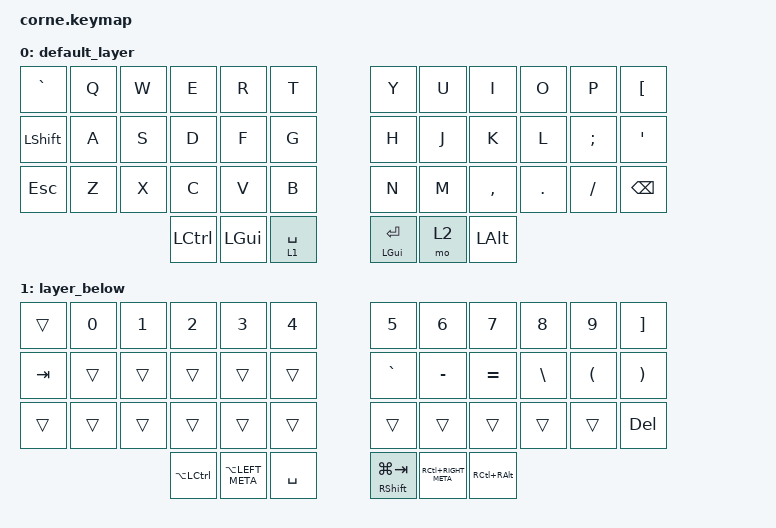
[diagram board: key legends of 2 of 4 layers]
/*
 * Copyright (c) 2020 The ZMK Contributors
 *
 * SPDX-License-Identifier: MIT
 */

#include <dt-bindings/zmk/mouse.h>
#include <behaviors.dtsi>
#include <dt-bindings/zmk/keys.h>
#include <dt-bindings/zmk/outputs.h>
#include <dt-bindings/zmk/pointing.h>

/ {
    behaviors {
        tp: tap_preferred {
            compatible = "zmk,behavior-hold-tap";
            label = "TAP_PREFERRED";
            #binding-cells = <2>;
            tapping-term-ms = <150>;
            quick-tap-ms = <0>;
            flavor = "tap-preferred";
            bindings = <&kp>, <&kp>;
        };
    };

    keymap {
        compatible = "zmk,keymap";

        default_layer {
            // -----------------------------------------------------------------------------------------
            // | TAB  |  Q  |  W  |  E  |  R  |    T    |   |  Y  |  U   |  I  |  O  |  P  |  [   |
            // | CTRL |  A  |  S  |  D  |  F  |    G    |   |  H  |  J   |  K  |  L  |  ;  |  '   |
            // | SHFT |  Z  |  X  |  C  |  V  |    B    |   |  N  |  M   |  ,  |  .  |  /  | BSPC |
            //                    | GUI | LWR | ALT/ENT |   | HYPER/SPC | BKSP  | RSE |

            bindings = <
&kp GRAVE       &kp Q  &kp W  &kp E      &kp R     &kp T          &kp Y           &kp U  &kp I      &kp O    &kp P     &kp LBKT
&kp LEFT_SHIFT  &kp A  &kp S  &kp D      &kp F     &kp G          &kp H           &kp J  &kp K      &kp L    &kp SEMI  &kp APOSTROPHE
&kp ESC         &kp Z  &kp X  &kp C      &kp V     &kp B          &kp N           &kp M  &kp COMMA  &kp DOT  &kp FSLH  &kp BSPC
                              &kp LCTRL  &kp LGUI  &lt 1 SPACE    &tp LGUI ENTER  &mo 2  &kp LALT
            >;
        };

        layer_below {
            // -----------------------------------------------------------------------------------------
            // |      |  0  |  1  |  2  |  3  |    4     |   |  5  |  6  |  7  |  8  |  9  |   ]   |
            // | TAB  |  1  |  2  |  3  |  4  |    5     |   |    |    |    |    |    |    |
            // |      |  6  |  7  |  8  |  9  |    0     |   |    |    |    |    |    |  |
            //                     | GUI |     | ALT/ENT |   |  | RSE | ALT |

            bindings = <
&trans   &kp N0  &kp N1  &kp N2         &kp N3             &kp N4       &kp N5                   &kp N6              &kp N7             &kp N8         &kp N9                &kp RBKT
&kp TAB  &trans  &trans  &trans         &trans             &trans       &kp GRAVE                &kp MINUS           &kp EQUAL          &kp BACKSLASH  &kp LEFT_PARENTHESIS  &kp RIGHT_PARENTHESIS
&trans   &trans  &trans  &trans         &trans             &trans       &trans                   &trans              &trans             &trans         &trans                &kp DEL
                         &kp LA(LCTRL)  &kp LA(LEFT_META)  &kp SPACE    &tp RIGHT_SHIFT LG(TAB)  &kp RC(RIGHT_META)  &kp RC(RIGHT_ALT)
            >;
        };

        layer_above {
            // -----------------------------------------------------------------------------------------
            // |       |  F1  |  F2  |  F3  |  F4  |  F5 |            |  F6  |  F7  |  F8  |  F9  |  F10  |   |
            // |       | Prev | Next | Vol - | Vol + | Play/Pause |   |      | LFT | DWN |  UP | RGT |     |     |
            // | BTCLR | BT1 | BT2 | BT3 | BT4 | BT5 |   |            |     |     |     |     |     |     |
            //                    |     |     |    |                  |     |     |     |

            bindings = <d
&trans  &kp F1      &kp F2      &kp F3         &kp F4        &kp F5         &kp F6                      &kp F7    &kp F8        &kp F9     &kp F10  &trans
&trans  &kp C_PREV  &kp C_NEXT  &kp C_VOL_DN   &kp C_VOL_UP  &kp C_PP       &kp LEFT                    &kp DOWN  &kp UP        &kp RIGHT  &none    &trans
&trans  &trans      &trans      &trans         &trans        &trans         &none                       &mkp MB1  &mkp MB2      &mkp MB3   &trans   &trans
                                &kp LA(LCTRL)  &kp LA(LGUI)  &lt 3 SPACE    &tp LS(LA(LC(LGUI))) ENTER  &trans    &kp LC(LALT)
            >;
        };

        layer_3 {
            bindings = <
&none   &bt BT_SEL 0  &bt BT_SEL 1  &bt BT_SEL 2  &bt BT_SEL 3  &bt BT_SEL 4    &trans                     &trans  &trans  &trans  &trans  &trans
&trans  &trans        &trans        &bt BT_PRV    &bt BT_NXT    &out OUT_TOG    &trans                     &trans  &trans  &trans  &trans  &trans
&trans  &trans        &trans        &trans        &trans        &trans          &trans                     &trans  &trans  &trans  &trans  &bt BT_CLR
                                    &trans        &trans        &trans          &kp LS(LA(LC(LG(ENTER))))  &trans  &transd
            >;
        };
    };
};
